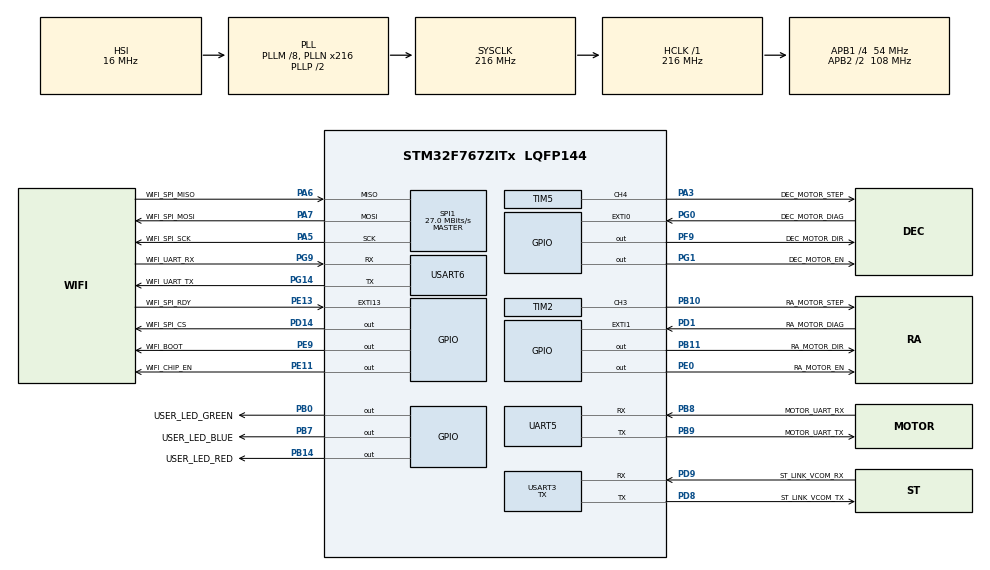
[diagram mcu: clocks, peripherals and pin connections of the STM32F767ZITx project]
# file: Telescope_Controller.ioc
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CORTEX_M7.CPU_DCache=Enabled
CORTEX_M7.CPU_ICache=Enabled
CORTEX_M7.Enable-Cortex_Memory_Protection_Unit_Region0_Settings=__NULL
CORTEX_M7.MPU_Control=__NULL
CRC.CRCLength=CRC_POLYLENGTH_8B
CRC.DefaultInitValueUse=DEFAULT_INIT_VALUE_DISABLE
CRC.DefaultPolynomialUse=DEFAULT_POLYNOMIAL_DISABLE
CRC.InputDataInversionMode=CRC_INPUTDATA_INVERSION_BYTE
Dma.Request0=SPI1_RX
Dma.Request1=SPI1_TX
Dma.Request2=USART3_TX
Dma.SPI1_RX.0.Direction=DMA_PERIPH_TO_MEMORY
Dma.SPI1_RX.0.FIFOMode=DMA_FIFOMODE_DISABLE
Dma.SPI1_RX.0.Instance=DMA2_Stream0
Dma.SPI1_RX.0.MemDataAlignment=DMA_MDATAALIGN_BYTE
Dma.SPI1_RX.0.MemInc=DMA_MINC_ENABLE
Dma.SPI1_RX.0.Mode=DMA_NORMAL
Dma.SPI1_RX.0.PeriphDataAlignment=DMA_PDATAALIGN_BYTE
Dma.SPI1_RX.0.PeriphInc=DMA_PINC_DISABLE
Dma.SPI1_RX.0.Priority=DMA_PRIORITY_HIGH
Dma.SPI1_TX.1.Direction=DMA_MEMORY_TO_PERIPH
Dma.SPI1_TX.1.FIFOMode=DMA_FIFOMODE_DISABLE
Dma.SPI1_TX.1.Instance=DMA2_Stream3
Dma.SPI1_TX.1.MemDataAlignment=DMA_MDATAALIGN_BYTE
Dma.SPI1_TX.1.MemInc=DMA_MINC_ENABLE
Dma.SPI1_TX.1.Mode=DMA_NORMAL
Dma.SPI1_TX.1.PeriphDataAlignment=DMA_PDATAALIGN_BYTE
Dma.SPI1_TX.1.PeriphInc=DMA_PINC_DISABLE
Dma.SPI1_TX.1.Priority=DMA_PRIORITY_MEDIUM
Dma.USART3_TX.2.Direction=DMA_MEMORY_TO_PERIPH
Dma.USART3_TX.2.FIFOMode=DMA_FIFOMODE_DISABLE
Dma.USART3_TX.2.Instance=DMA1_Stream3
Dma.USART3_TX.2.MemDataAlignment=DMA_MDATAALIGN_BYTE
Dma.USART3_TX.2.MemInc=DMA_MINC_ENABLE
Dma.USART3_TX.2.Mode=DMA_NORMAL
Dma.USART3_TX.2.PeriphDataAlignment=DMA_PDATAALIGN_BYTE
Dma.USART3_TX.2.PeriphInc=DMA_PINC_DISABLE
Dma.USART3_TX.2.Priority=DMA_PRIORITY_LOW
Mcu.Family=STM32F7
Mcu.Name=STM32F767ZITx
Mcu.Package=LQFP144
NVIC.DMA1_Stream3_IRQn=true\:7\:0\:true\:false\:true\:false\:true\:true
NVIC.DMA2_Stream0_IRQn=true\:6\:0\:true\:false\:true\:false\:true\:true
NVIC.DMA2_Stream3_IRQn=true\:6\:0\:true\:false\:true\:false\:true\:true
NVIC.EXTI0_IRQn=true\:5\:0\:true\:false\:true\:true\:true\:true
NVIC.EXTI15_10_IRQn=true\:6\:0\:true\:false\:true\:true\:true\:true
NVIC.EXTI1_IRQn=true\:5\:0\:true\:false\:true\:true\:true\:true
NVIC.PriorityGroup=NVIC_PRIORITYGROUP_4
NVIC.SPI1_IRQn=true\:6\:0\:true\:false\:true\:true\:true\:true
NVIC.TIM6_DAC_IRQn=true\:4\:0\:true\:false\:true\:false\:true\:true
NVIC.TimeBase=TIM6_DAC_IRQn
NVIC.TimeBaseIP=TIM6
NVIC.USART3_IRQn=true\:7\:0\:true\:false\:true\:true\:true\:true
PA13.Mode=Trace_Asynchronous_SW
PA13.Signal=SYS_JTMS-SWDIO
PA14.Mode=Trace_Asynchronous_SW
PA14.Signal=SYS_JTCK-SWCLK
PA3.GPIO_Label=DEC_MOTOR_STEP
PA3.Signal=S_TIM5_CH4
PA5.GPIO_Label=WIFI_SPI_SCK
PA5.Mode=Full_Duplex_Master
PA5.Signal=SPI1_SCK
PA6.GPIO_Label=WIFI_SPI_MISO
PA6.Mode=Full_Duplex_Master
PA6.Signal=SPI1_MISO
PA7.GPIO_Label=WIFI_SPI_MOSI
PA7.Mode=Full_Duplex_Master
PA7.Signal=SPI1_MOSI
PB0.GPIO_Label=USER_LED_GREEN
PB0.Signal=GPIO_Output
PB10.GPIO_Label=RA_MOTOR_STEP
PB10.Signal=S_TIM2_CH3
PB11.GPIO_Label=RA_MOTOR_DIR
PB11.Signal=GPIO_Output
PB14.GPIO_Label=USER_LED_RED
PB14.Signal=GPIO_Output
PB3.Mode=Trace_Asynchronous_SW
PB3.Signal=SYS_JTDO-SWO
PB7.GPIO_Label=USER_LED_BLUE
PB7.Signal=GPIO_Output
PB8.GPIO_Label=MOTOR_UART_RX
PB8.Mode=Asynchronous
PB8.Signal=UART5_RX
PB9.GPIO_Label=MOTOR_UART_TX
PB9.Mode=Asynchronous
PB9.Signal=UART5_TX
PC14/OSC32_IN.Mode=LSE-External-Oscillator
PC14/OSC32_IN.Signal=RCC_OSC32_IN
PC15/OSC32_OUT.Mode=LSE-External-Oscillator
PC15/OSC32_OUT.Signal=RCC_OSC32_OUT
PD1.GPIO_Label=RA_MOTOR_DIAG
PD1.GPIO_PuPd=GPIO_PULLDOWN
PD1.Signal=GPXTI1
PD14.GPIO_Label=WIFI_SPI_CS
PD14.PinState=GPIO_PIN_SET
PD14.Signal=GPIO_Output
PD8.GPIO_Label=ST_LINK_VCOM_TX
PD8.Mode=Asynchronous
PD8.Signal=USART3_TX
PD9.GPIO_Label=ST_LINK_VCOM_RX
PD9.Mode=Asynchronous
PD9.Signal=USART3_RX
PE0.GPIO_Label=RA_MOTOR_EN
PE0.GPIO_PuPd=GPIO_NOPULL
PE0.PinState=GPIO_PIN_SET
PE0.Signal=GPIO_Output
PE11.GPIO_Label=WIFI_CHIP_EN
PE11.Signal=GPIO_Output
PE13.GPIO_Label=WIFI_SPI_RDY
PE13.Signal=GPXTI13
PE9.GPIO_Label=WIFI_BOOT
PE9.Signal=GPIO_Output
PF9.GPIO_Label=DEC_MOTOR_DIR
PF9.Signal=GPIO_Output
PG0.GPIO_Label=DEC_MOTOR_DIAG
PG0.GPIO_PuPd=GPIO_PULLDOWN
PG0.Signal=GPXTI0
PG1.GPIO_Label=DEC_MOTOR_EN
PG1.GPIO_PuPd=GPIO_NOPULL
PG1.PinState=GPIO_PIN_SET
PG1.Signal=GPIO_Output
PG14.GPIO_Label=WIFI_UART_TX
PG14.Mode=Asynchronous
PG14.Signal=USART6_TX
PG9.GPIO_Label=WIFI_UART_RX
PG9.Mode=Asynchronous
PG9.Signal=USART6_RX
PH0/OSC_IN.Mode=HSE-External-Clock-Source
PH0/OSC_IN.Signal=RCC_OSC_IN
PH1/OSC_OUT.Mode=HSE-External-Clock-Source
PH1/OSC_OUT.Signal=RCC_OSC_OUT
ProjectManager.HeapSize=0x200
ProjectManager.StackSize=0x400
ProjectManager.TargetToolchain=CMake
RCC.AHBFreq_Value=216000000
RCC.APB1CLKDivider=RCC_HCLK_DIV4
RCC.APB1Freq_Value=54000000
RCC.APB1TimFreq_Value=108000000
RCC.APB2CLKDivider=RCC_HCLK_DIV2
RCC.APB2Freq_Value=108000000
RCC.APB2TimFreq_Value=216000000
RCC.CortexFreq_Value=216000000
RCC.HCLKFreq_Value=216000000
RCC.HSE_VALUE=8000000
RCC.HSI_VALUE=16000000
RCC.PLLM=8
RCC.PLLN=216
RCC.SYSCLKFreq_VALUE=216000000
RCC.SYSCLKSource=RCC_SYSCLKSOURCE_PLLCLK
RCC.USBFreq_Value=216000000
RCC.VCOOutputFreq_Value=432000000
SH.S_TIM2_CH3.0=TIM2_CH3,PWM Generation3 CH3
SH.S_TIM5_CH4.0=TIM5_CH4,PWM Generation4 CH4
SPI1.BaudRatePrescaler=SPI_BAUDRATEPRESCALER_4
SPI1.CalculateBaudRate=27.0 MBits/s
SPI1.DataSize=SPI_DATASIZE_8BIT
SPI1.Direction=SPI_DIRECTION_2LINES
SPI1.Mode=SPI_MODE_MASTER
SPI1.VirtualType=VM_MASTER
TIM2.AutoReloadPreload=TIM_AUTORELOAD_PRELOAD_ENABLE
TIM2.Channel-PWM\ Generation3\ CH3=TIM_CHANNEL_3
TIM5.AutoReloadPreload=TIM_AUTORELOAD_PRELOAD_ENABLE
TIM5.Channel-PWM\ Generation4\ CH4=TIM_CHANNEL_4
USART3.Mode=MODE_TX
USART3.VirtualMode-Asynchronous=VM_ASYNC
USART6.VirtualMode-Asynchronous=VM_ASYNC
VP_CRC_VS_CRC.Mode=CRC_Activate
VP_SYS_VS_tim6.Mode=TIM6
board=custom

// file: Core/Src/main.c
/* USER CODE BEGIN Header */
/**
  ******************************************************************************
  * @file           : main.c
  * @brief          : Main program body
  ******************************************************************************
  * @attention
  *
  * Copyright (c) 2026 STMicroelectronics.
  * All rights reserved.
  *
  * This software is licensed under terms that can be found in the LICENSE file
  * in the root directory of this software component.
  * If no LICENSE file comes with this software, it is provided AS-IS.
  *
  ******************************************************************************
  */
/* USER CODE END Header */
#include "main.h"

CRC_HandleTypeDef hcrc;

SPI_HandleTypeDef hspi1;
DMA_HandleTypeDef hdma_spi1_rx;
DMA_HandleTypeDef hdma_spi1_tx;

TIM_HandleTypeDef htim2;
TIM_HandleTypeDef htim5;

UART_HandleTypeDef huart5;
UART_HandleTypeDef huart3;
UART_HandleTypeDef huart6;
DMA_HandleTypeDef hdma_usart3_tx;

void SystemClock_Config(void);
static void MX_GPIO_Init(void);
static void MX_DMA_Init(void);
static void MX_SPI1_Init(void);
static void MX_TIM2_Init(void);
static void MX_USART3_UART_Init(void);
static void MX_TIM5_Init(void);
static void MX_UART5_Init(void);
static void MX_USART6_UART_Init(void);
static void MX_CRC_Init(void);

int main(void)
{

  /* Enable the CPU Cache */

  /* Enable I-Cache---------------------------------------------------------*/
  SCB_EnableICache();

  /* Enable D-Cache---------------------------------------------------------*/
  SCB_EnableDCache();

  /* MCU Configuration--------------------------------------------------------*/

  /* Reset of all peripherals, Initializes the Flash interface and the Systick. */
  HAL_Init();

  /* Configure the system clock */
  SystemClock_Config();

  /* Initialize all configured peripherals */
  MX_GPIO_Init();
  MX_DMA_Init();
  MX_SPI1_Init();
  MX_TIM2_Init();
  MX_USART3_UART_Init();
  MX_TIM5_Init();
  MX_UART5_Init();
  MX_USART6_UART_Init();
  MX_CRC_Init();

  /* Infinite loop */
  /* USER CODE BEGIN WHILE */
  while (1)
  {

    HAL_GPIO_TogglePin(USER_LED_RED_GPIO_Port, USER_LED_RED_Pin);
	  HAL_GPIO_TogglePin(USER_LED_GREEN_GPIO_Port, USER_LED_GREEN_Pin);
	  HAL_GPIO_TogglePin(USER_LED_BLUE_GPIO_Port, USER_LED_BLUE_Pin);
	  HAL_Delay(1000);

    /* USER CODE END WHILE */

  }
}

void SystemClock_Config(void)
{
  RCC_OscInitTypeDef RCC_OscInitStruct = {0};
  RCC_ClkInitTypeDef RCC_ClkInitStruct = {0};

  /** Configure LSE Drive Capability
  */
  HAL_PWR_EnableBkUpAccess();

  /** Configure the main internal regulator output voltage
  */
  __HAL_RCC_PWR_CLK_ENABLE();
  __HAL_PWR_VOLTAGESCALING_CONFIG(PWR_REGULATOR_VOLTAGE_SCALE1);

  /** Initializes the RCC Oscillators according to the specified parameters
  * in the RCC_OscInitTypeDef structure.
  */
  RCC_OscInitStruct.OscillatorType = RCC_OSCILLATORTYPE_HSI;
  RCC_OscInitStruct.HSIState = RCC_HSI_ON;
  RCC_OscInitStruct.HSICalibrationValue = RCC_HSICALIBRATION_DEFAULT;
  RCC_OscInitStruct.PLL.PLLState = RCC_PLL_ON;
  RCC_OscInitStruct.PLL.PLLSource = RCC_PLLSOURCE_HSI;
  RCC_OscInitStruct.PLL.PLLM = 8;
  RCC_OscInitStruct.PLL.PLLN = 216;
  RCC_OscInitStruct.PLL.PLLP = RCC_PLLP_DIV2;
  RCC_OscInitStruct.PLL.PLLQ = 2;
  RCC_OscInitStruct.PLL.PLLR = 2;
  if (HAL_RCC_OscConfig(&RCC_OscInitStruct) != HAL_OK)
  {
    Error_Handler();
  }

  /** Activate the Over-Drive mode
  */
  if (HAL_PWREx_EnableOverDrive() != HAL_OK)
  {
    Error_Handler();
  }

  /** Initializes the CPU, AHB and APB buses clocks
  */
  RCC_ClkInitStruct.ClockType = RCC_CLOCKTYPE_HCLK|RCC_CLOCKTYPE_SYSCLK
                              |RCC_CLOCKTYPE_PCLK1|RCC_CLOCKTYPE_PCLK2;
  RCC_ClkInitStruct.SYSCLKSource = RCC_SYSCLKSOURCE_PLLCLK;
  RCC_ClkInitStruct.AHBCLKDivider = RCC_SYSCLK_DIV1;
  RCC_ClkInitStruct.APB1CLKDivider = RCC_HCLK_DIV4;
  RCC_ClkInitStruct.APB2CLKDivider = RCC_HCLK_DIV2;

  if (HAL_RCC_ClockConfig(&RCC_ClkInitStruct, FLASH_LATENCY_7) != HAL_OK)
  {
    Error_Handler();
  }
}

static void MX_CRC_Init(void)
{

  hcrc.Instance = CRC;
  hcrc.Init.DefaultPolynomialUse = DEFAULT_POLYNOMIAL_DISABLE;
  hcrc.Init.DefaultInitValueUse = DEFAULT_INIT_VALUE_DISABLE;
  hcrc.Init.GeneratingPolynomial = 7;
  hcrc.Init.CRCLength = CRC_POLYLENGTH_8B;
  hcrc.Init.InitValue = 0;
  hcrc.Init.InputDataInversionMode = CRC_INPUTDATA_INVERSION_BYTE;
  hcrc.Init.OutputDataInversionMode = CRC_OUTPUTDATA_INVERSION_DISABLE;
  hcrc.InputDataFormat = CRC_INPUTDATA_FORMAT_BYTES;
  if (HAL_CRC_Init(&hcrc) != HAL_OK)
  {
    Error_Handler();
  }

}

static void MX_SPI1_Init(void)
{

  /* SPI1 parameter configuration*/
  hspi1.Instance = SPI1;
  hspi1.Init.Mode = SPI_MODE_MASTER;
  hspi1.Init.Direction = SPI_DIRECTION_2LINES;
  hspi1.Init.DataSize = SPI_DATASIZE_8BIT;
  hspi1.Init.CLKPolarity = SPI_POLARITY_LOW;
  hspi1.Init.CLKPhase = SPI_PHASE_1EDGE;
  hspi1.Init.NSS = SPI_NSS_SOFT;
  hspi1.Init.BaudRatePrescaler = SPI_BAUDRATEPRESCALER_4;
  hspi1.Init.FirstBit = SPI_FIRSTBIT_MSB;
  hspi1.Init.TIMode = SPI_TIMODE_DISABLE;
  hspi1.Init.CRCCalculation = SPI_CRCCALCULATION_DISABLE;
  hspi1.Init.CRCPolynomial = 7;
  hspi1.Init.CRCLength = SPI_CRC_LENGTH_DATASIZE;
  hspi1.Init.NSSPMode = SPI_NSS_PULSE_ENABLE;
  if (HAL_SPI_Init(&hspi1) != HAL_OK)
  {
    Error_Handler();
  }

}

static void MX_TIM2_Init(void)
{

  TIM_MasterConfigTypeDef sMasterConfig = {0};
  TIM_OC_InitTypeDef sConfigOC = {0};

  htim2.Instance = TIM2;
  htim2.Init.Prescaler = 0;
  htim2.Init.CounterMode = TIM_COUNTERMODE_UP;
  htim2.Init.Period = 4294967295;
  htim2.Init.ClockDivision = TIM_CLOCKDIVISION_DIV1;
  htim2.Init.AutoReloadPreload = TIM_AUTORELOAD_PRELOAD_ENABLE;
  if (HAL_TIM_PWM_Init(&htim2) != HAL_OK)
  {
    Error_Handler();
  }
  sMasterConfig.MasterOutputTrigger = TIM_TRGO_RESET;
  sMasterConfig.MasterSlaveMode = TIM_MASTERSLAVEMODE_DISABLE;
  if (HAL_TIMEx_MasterConfigSynchronization(&htim2, &sMasterConfig) != HAL_OK)
  {
    Error_Handler();
  }
  sConfigOC.OCMode = TIM_OCMODE_PWM1;
  sConfigOC.Pulse = 0;
  sConfigOC.OCPolarity = TIM_OCPOLARITY_HIGH;
  sConfigOC.OCFastMode = TIM_OCFAST_DISABLE;
  if (HAL_TIM_PWM_ConfigChannel(&htim2, &sConfigOC, TIM_CHANNEL_3) != HAL_OK)
  {
    Error_Handler();
  }
  HAL_TIM_MspPostInit(&htim2);

}

static void MX_TIM5_Init(void)
{

  TIM_MasterConfigTypeDef sMasterConfig = {0};
  TIM_OC_InitTypeDef sConfigOC = {0};

  htim5.Instance = TIM5;
  htim5.Init.Prescaler = 0;
  htim5.Init.CounterMode = TIM_COUNTERMODE_UP;
  htim5.Init.Period = 4294967295;
  htim5.Init.ClockDivision = TIM_CLOCKDIVISION_DIV1;
  htim5.Init.AutoReloadPreload = TIM_AUTORELOAD_PRELOAD_ENABLE;
  if (HAL_TIM_PWM_Init(&htim5) != HAL_OK)
  {
    Error_Handler();
  }
  sMasterConfig.MasterOutputTrigger = TIM_TRGO_RESET;
  sMasterConfig.MasterSlaveMode = TIM_MASTERSLAVEMODE_DISABLE;
  if (HAL_TIMEx_MasterConfigSynchronization(&htim5, &sMasterConfig) != HAL_OK)
  {
    Error_Handler();
  }
  sConfigOC.OCMode = TIM_OCMODE_PWM1;
  sConfigOC.Pulse = 0;
  sConfigOC.OCPolarity = TIM_OCPOLARITY_HIGH;
  sConfigOC.OCFastMode = TIM_OCFAST_DISABLE;
  if (HAL_TIM_PWM_ConfigChannel(&htim5, &sConfigOC, TIM_CHANNEL_4) != HAL_OK)
  {
    Error_Handler();
  }
  HAL_TIM_MspPostInit(&htim5);

}

static void MX_UART5_Init(void)
{

  huart5.Instance = UART5;
  huart5.Init.BaudRate = 115200;
  huart5.Init.WordLength = UART_WORDLENGTH_8B;
  huart5.Init.StopBits = UART_STOPBITS_1;
  huart5.Init.Parity = UART_PARITY_NONE;
  huart5.Init.Mode = UART_MODE_TX_RX;
  huart5.Init.HwFlowCtl = UART_HWCONTROL_NONE;
  huart5.Init.OverSampling = UART_OVERSAMPLING_16;
  huart5.Init.OneBitSampling = UART_ONE_BIT_SAMPLE_DISABLE;
  huart5.AdvancedInit.AdvFeatureInit = UART_ADVFEATURE_NO_INIT;
  if (HAL_UART_Init(&huart5) != HAL_OK)
  {
    Error_Handler();
  }

}

static void MX_USART3_UART_Init(void)
{

  huart3.Instance = USART3;
  huart3.Init.BaudRate = 115200;
  huart3.Init.WordLength = UART_WORDLENGTH_8B;
  huart3.Init.StopBits = UART_STOPBITS_1;
  huart3.Init.Parity = UART_PARITY_NONE;
  huart3.Init.Mode = UART_MODE_TX;
  huart3.Init.HwFlowCtl = UART_HWCONTROL_NONE;
  huart3.Init.OverSampling = UART_OVERSAMPLING_16;
  huart3.Init.OneBitSampling = UART_ONE_BIT_SAMPLE_DISABLE;
  huart3.AdvancedInit.AdvFeatureInit = UART_ADVFEATURE_NO_INIT;
  if (HAL_UART_Init(&huart3) != HAL_OK)
  {
    Error_Handler();
  }

}

static void MX_USART6_UART_Init(void)
{

  huart6.Instance = USART6;
  huart6.Init.BaudRate = 115200;
  huart6.Init.WordLength = UART_WORDLENGTH_8B;
  huart6.Init.StopBits = UART_STOPBITS_1;
  huart6.Init.Parity = UART_PARITY_NONE;
  huart6.Init.Mode = UART_MODE_TX_RX;
  huart6.Init.HwFlowCtl = UART_HWCONTROL_NONE;
  huart6.Init.OverSampling = UART_OVERSAMPLING_16;
  huart6.Init.OneBitSampling = UART_ONE_BIT_SAMPLE_DISABLE;
  huart6.AdvancedInit.AdvFeatureInit = UART_ADVFEATURE_NO_INIT;
  if (HAL_UART_Init(&huart6) != HAL_OK)
  {
    Error_Handler();
  }

}

static void MX_DMA_Init(void)
{

  /* DMA controller clock enable */
  __HAL_RCC_DMA2_CLK_ENABLE();
  __HAL_RCC_DMA1_CLK_ENABLE();

  /* DMA interrupt init */
  /* DMA1_Stream3_IRQn interrupt configuration */
  HAL_NVIC_SetPriority(DMA1_Stream3_IRQn, 7, 0);
  HAL_NVIC_EnableIRQ(DMA1_Stream3_IRQn);
  /* DMA2_Stream0_IRQn interrupt configuration */
  HAL_NVIC_SetPriority(DMA2_Stream0_IRQn, 6, 0);
  HAL_NVIC_EnableIRQ(DMA2_Stream0_IRQn);
  /* DMA2_Stream3_IRQn interrupt configuration */
  HAL_NVIC_SetPriority(DMA2_Stream3_IRQn, 6, 0);
  HAL_NVIC_EnableIRQ(DMA2_Stream3_IRQn);

}

static void MX_GPIO_Init(void)
{
  GPIO_InitTypeDef GPIO_InitStruct = {0};

  /* GPIO Ports Clock Enable */
  __HAL_RCC_GPIOC_CLK_ENABLE();
  __HAL_RCC_GPIOF_CLK_ENABLE();
  __HAL_RCC_GPIOH_CLK_ENABLE();
  __HAL_RCC_GPIOA_CLK_ENABLE();
  __HAL_RCC_GPIOB_CLK_ENABLE();
  __HAL_RCC_GPIOG_CLK_ENABLE();
  __HAL_RCC_GPIOE_CLK_ENABLE();
  __HAL_RCC_GPIOD_CLK_ENABLE();

  /*Configure GPIO pin Output Level */
  HAL_GPIO_WritePin(DEC_MOTOR_DIR_GPIO_Port, DEC_MOTOR_DIR_Pin, GPIO_PIN_RESET);

  /*Configure GPIO pin Output Level */
  HAL_GPIO_WritePin(GPIOB, USER_LED_GREEN_Pin|RA_MOTOR_DIR_Pin|USER_LED_RED_Pin|USER_LED_BLUE_Pin, GPIO_PIN_RESET);

  /*Configure GPIO pin Output Level */
  HAL_GPIO_WritePin(DEC_MOTOR_EN_GPIO_Port, DEC_MOTOR_EN_Pin, GPIO_PIN_SET);

  /*Configure GPIO pin Output Level */
  HAL_GPIO_WritePin(GPIOE, WIFI_BOOT_Pin|WIFI_CHIP_EN_Pin, GPIO_PIN_RESET);

  /*Configure GPIO pin Output Level */
  HAL_GPIO_WritePin(WIFI_SPI_CS_GPIO_Port, WIFI_SPI_CS_Pin, GPIO_PIN_SET);

  /*Configure GPIO pin Output Level */
  HAL_GPIO_WritePin(RA_MOTOR_EN_GPIO_Port, RA_MOTOR_EN_Pin, GPIO_PIN_SET);

  /*Configure GPIO pin : DEC_MOTOR_DIR_Pin */
  GPIO_InitStruct.Pin = DEC_MOTOR_DIR_Pin;
  GPIO_InitStruct.Mode = GPIO_MODE_OUTPUT_PP;
  GPIO_InitStruct.Pull = GPIO_NOPULL;
  GPIO_InitStruct.Speed = GPIO_SPEED_FREQ_LOW;
  HAL_GPIO_Init(DEC_MOTOR_DIR_GPIO_Port, &GPIO_InitStruct);

  /*Configure GPIO pins : USER_LED_GREEN_Pin RA_MOTOR_DIR_Pin USER_LED_RED_Pin USER_LED_BLUE_Pin */
  GPIO_InitStruct.Pin = USER_LED_GREEN_Pin|RA_MOTOR_DIR_Pin|USER_LED_RED_Pin|USER_LED_BLUE_Pin;
  GPIO_InitStruct.Mode = GPIO_MODE_OUTPUT_PP;
  GPIO_InitStruct.Pull = GPIO_NOPULL;
  GPIO_InitStruct.Speed = GPIO_SPEED_FREQ_LOW;
  HAL_GPIO_Init(GPIOB, &GPIO_InitStruct);

  /*Configure GPIO pin : DEC_MOTOR_DIAG_Pin */
  GPIO_InitStruct.Pin = DEC_MOTOR_DIAG_Pin;
  GPIO_InitStruct.Mode = GPIO_MODE_IT_RISING;
  GPIO_InitStruct.Pull = GPIO_PULLDOWN;
  HAL_GPIO_Init(DEC_MOTOR_DIAG_GPIO_Port, &GPIO_InitStruct);

  /*Configure GPIO pin : DEC_MOTOR_EN_Pin */
  GPIO_InitStruct.Pin = DEC_MOTOR_EN_Pin;
  GPIO_InitStruct.Mode = GPIO_MODE_OUTPUT_PP;
  GPIO_InitStruct.Pull = GPIO_NOPULL;
  GPIO_InitStruct.Speed = GPIO_SPEED_FREQ_LOW;
  HAL_GPIO_Init(DEC_MOTOR_EN_GPIO_Port, &GPIO_InitStruct);

  /*Configure GPIO pins : WIFI_BOOT_Pin WIFI_CHIP_EN_Pin RA_MOTOR_EN_Pin */
  GPIO_InitStruct.Pin = WIFI_BOOT_Pin|WIFI_CHIP_EN_Pin|RA_MOTOR_EN_Pin;
  GPIO_InitStruct.Mode = GPIO_MODE_OUTPUT_PP;
  GPIO_InitStruct.Pull = GPIO_NOPULL;
  GPIO_InitStruct.Speed = GPIO_SPEED_FREQ_LOW;
  HAL_GPIO_Init(GPIOE, &GPIO_InitStruct);

  /*Configure GPIO pin : WIFI_SPI_RDY_Pin */
  GPIO_InitStruct.Pin = WIFI_SPI_RDY_Pin;
  GPIO_InitStruct.Mode = GPIO_MODE_IT_RISING;
  GPIO_InitStruct.Pull = GPIO_NOPULL;
  HAL_GPIO_Init(WIFI_SPI_RDY_GPIO_Port, &GPIO_InitStruct);

  /*Configure GPIO pin : WIFI_SPI_CS_Pin */
  GPIO_InitStruct.Pin = WIFI_SPI_CS_Pin;
  GPIO_InitStruct.Mode = GPIO_MODE_OUTPUT_PP;
  GPIO_InitStruct.Pull = GPIO_NOPULL;
  GPIO_InitStruct.Speed = GPIO_SPEED_FREQ_LOW;
  HAL_GPIO_Init(WIFI_SPI_CS_GPIO_Port, &GPIO_InitStruct);

  /*Configure GPIO pin : RA_MOTOR_DIAG_Pin */
  GPIO_InitStruct.Pin = RA_MOTOR_DIAG_Pin;
  GPIO_InitStruct.Mode = GPIO_MODE_IT_RISING;
  GPIO_InitStruct.Pull = GPIO_PULLDOWN;
  HAL_GPIO_Init(RA_MOTOR_DIAG_GPIO_Port, &GPIO_InitStruct);

  /* EXTI interrupt init*/
  HAL_NVIC_SetPriority(EXTI0_IRQn, 5, 0);
  HAL_NVIC_EnableIRQ(EXTI0_IRQn);

  HAL_NVIC_SetPriority(EXTI1_IRQn, 5, 0);
  HAL_NVIC_EnableIRQ(EXTI1_IRQn);

  HAL_NVIC_SetPriority(EXTI15_10_IRQn, 6, 0);
  HAL_NVIC_EnableIRQ(EXTI15_10_IRQn);

}

void HAL_TIM_PeriodElapsedCallback(TIM_HandleTypeDef *htim)
{
  if (htim->Instance == TIM6)
  {
    HAL_IncTick();
  }
}

void Error_Handler(void)
{
  __disable_irq();
  while (1)
  {
  }
}
